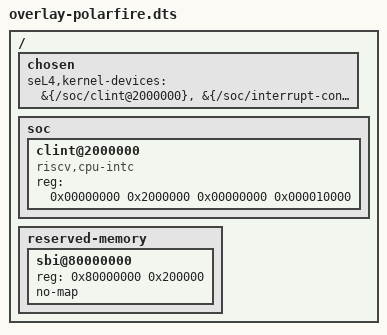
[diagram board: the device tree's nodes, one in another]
/*
 * Copyright 2020, DornerWorks
 * Copyright 2021, HENSOLDT Cyber
 *
 * SPDX-License-Identifier: GPL-2.0-only
 */

/ {
	chosen {
		seL4,kernel-devices =
            &{/soc/clint@2000000},
		    &{/soc/interrupt-controller@c000000};
	};

    /*
     * According to the "PolarFire SoC MSS Technical Reference Manual"
     * (revision H), the CLINT is mapped from 0x0200_0000 to 0x0200_FFFF.
     */
    soc {
        clint@2000000 {
            compatible = "riscv,cpu-intc";
            reg = <0x00000000 0x2000000 0x00000000 0x000010000>;
        };
    };

    /* Reserve 2 MiB for SBI at the start of RAM (0x80000000 - 0x80200000). This
     * is exactly one "megapage" in the MMU table. It leaves plenty of space for
     * further SBI experimenting, given the known usage (as of June 2021) is:
     * - BBL: 76 KiB (= 0x13000)
     * - OpenSBI: 128 KiB (= 0x20000) with PMP protection
     */
    reserved-memory {
        #address-cells = <0x01>;
        #size-cells = <0x01>;
        ranges;
        sbi@80000000 {
            reg = <0x80000000 0x200000>;
            no-map;
        };
    };
};
